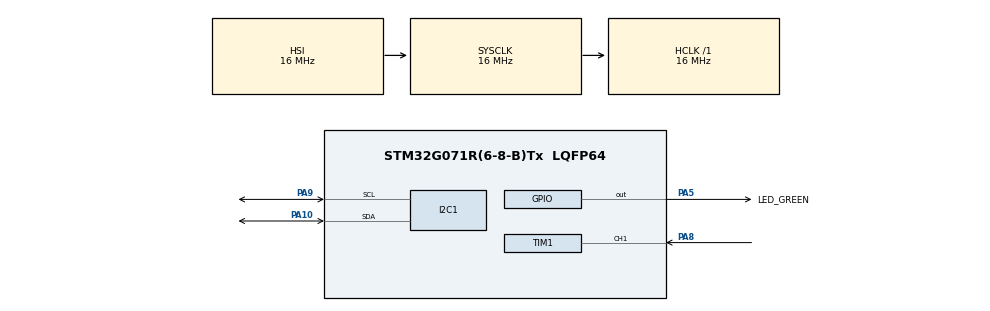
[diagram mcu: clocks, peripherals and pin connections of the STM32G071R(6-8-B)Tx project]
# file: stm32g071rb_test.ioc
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Mcu.Family=STM32G0
Mcu.Name=STM32G071R(6-8-B)Tx
Mcu.Package=LQFP64
NVIC.I2C1_IRQn=true\:0\:0\:false\:false\:true\:true\:true
NVIC.TIM1_BRK_UP_TRG_COM_IRQn=true\:0\:0\:false\:false\:true\:true\:true
NVIC.TIM1_CC_IRQn=true\:0\:0\:false\:false\:true\:true\:true
PA10.Mode=I2C
PA10.Signal=I2C1_SDA
PA13.GPIO_Label=TMS
PA13.Signal=SYS_SWDIO
PA14-BOOT0.GPIO_Label=TCK
PA14-BOOT0.Signal=SYS_SWCLK
PA2.GPIO_Label=USART2_TX [STLK_TX]
PA2.Signal=USART2_TX
PA3.GPIO_Label=USART2_RX [STLK_RX]
PA3.Signal=USART2_RX
PA5.GPIO_Label=LED_GREEN
PA5.GPIO_Speed=GPIO_SPEED_FREQ_HIGH
PA5.Signal=GPIO_Output
PA8.Signal=S_TIM1_CH1
PA9.Mode=I2C
PA9.Signal=I2C1_SCL
PC13.Signal=SYS_WKUP2
PC14-OSC32_IN\ (PC14).Signal=RCC_OSC32_IN
PC15-OSC32_OUT\ (PC15).Signal=RCC_OSC32_OUT
PF0-OSC_IN\ (PF0).GPIO_Label=MCO
PF0-OSC_IN\ (PF0).Signal=RCC_OSC_IN
ProjectManager.HeapSize=0x200
ProjectManager.StackSize=0x400
ProjectManager.TargetToolchain=STM32CubeIDE
RCC.AHBFreq_Value=16000000
RCC.CortexFreq_Value=16000000
RCC.EXTERNAL_CLOCK_VALUE=12288000
RCC.HCLKFreq_Value=16000000
RCC.HSE_VALUE=8000000
RCC.HSI_VALUE=16000000
RCC.LSE_VALUE=32768
RCC.SYSCLKFreq_VALUE=16000000
RCC.VCOOutputFreq_Value=128000000
SH.S_TIM1_CH1.0=TIM1_CH1,Input_Capture1_from_TI1
TIM1.Channel-Input_Capture1_from_TI1=TIM_CHANNEL_1
VP_SYS_VS_DBSignals.Mode=DisableDeadBatterySignals
VP_TIM1_VS_ClockSourceINT.Mode=Internal
VP_TIM1_VS_ClockSourceITR.Mode=TriggerSource_ITR0
VP_TIM1_VS_ControllerModeTrigger.Mode=Trigger Mode
board=NUCLEO-G071RB

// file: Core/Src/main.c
/* USER CODE BEGIN Header */
/**
  ******************************************************************************
  * @file           : main.c
  * @brief          : Main program body
  ******************************************************************************
  * @attention
  *
  * <h2><center>&copy; Copyright (c) 2021 STMicroelectronics.
  * All rights reserved.</center></h2>
  *
  * This software component is licensed by ST under BSD 3-Clause license,
  * the "License"; You may not use this file except in compliance with the
  * License. You may obtain a copy of the License at:
  *                        opensource.org/licenses/BSD-3-Clause
  *
  ******************************************************************************
  */
/* USER CODE END Header */
#include "main.h"
#include<stdlib.h>
#include<stdio.h>

I2C_HandleTypeDef hi2c1;

TIM_HandleTypeDef htim1;

void SystemClock_Config(void);
static void MX_GPIO_Init(void);
static void MX_I2C1_Init(void);
static void MX_TIM1_Init(void);

I2C_HandleTypeDef handle_i2c;

int main(void)
{

  /* MCU Configuration--------------------------------------------------------*/

  /* Reset of all peripherals, Initializes the Flash interface and the Systick. */
  HAL_Init();

  /* Configure the system clock */
  SystemClock_Config();

  /* Initialize all configured peripherals */
  MX_GPIO_Init();
  MX_I2C1_Init();
  MX_TIM1_Init();

  /* Infinite loop */
  /* USER CODE BEGIN WHILE */
  int slave_id = 0x01, i;
  uint8_t reg_buf[12];
  uint64_t final_data_sample;
  HAL_PWR_EnterSLEEPMode(PWR_LOWPOWERREGULATOR_ON, PWR_SLEEPENTRY_WFI);
  while (1)
  {
    /* USER CODE END WHILE */
	  if(i2c_read)
	  {
		  reg_buf[0] = 0x07;
		  final_data_sample=0;
		  HAL_I2C_Master_Transmit(&handle_i2c, slave_id, reg_buf, 1, HAL_MAX_DELAY);

		  for(i=0; i<100; i++)
		  {
			  HAL_I2C_Master_Receive(&handle_i2c, slave_id, reg_buf, 1, HAL_MAX_DELAY);
			  final_data_sample += (uint64_t)reg_buf[0];
		  }
		  printf("The final sampled I2C data is %llu\r\n",final_data_sample/100);
		  i2c_read = 0;
	  }
	  HAL_PWR_EnterSLEEPMode(PWR_LOWPOWERREGULATOR_ON, PWR_SLEEPENTRY_WFI);

  }
}

void SystemClock_Config(void)
{
  RCC_OscInitTypeDef RCC_OscInitStruct = {0};
  RCC_ClkInitTypeDef RCC_ClkInitStruct = {0};
  RCC_PeriphCLKInitTypeDef PeriphClkInit = {0};

  /** Configure the main internal regulator output voltage
  */
  HAL_PWREx_ControlVoltageScaling(PWR_REGULATOR_VOLTAGE_SCALE1);
  /** Initializes the RCC Oscillators according to the specified parameters
  * in the RCC_OscInitTypeDef structure.
  */
  RCC_OscInitStruct.OscillatorType = RCC_OSCILLATORTYPE_HSI;
  RCC_OscInitStruct.HSIState = RCC_HSI_ON;
  RCC_OscInitStruct.HSIDiv = RCC_HSI_DIV1;
  RCC_OscInitStruct.HSICalibrationValue = RCC_HSICALIBRATION_DEFAULT;
  RCC_OscInitStruct.PLL.PLLState = RCC_PLL_NONE;
  if (HAL_RCC_OscConfig(&RCC_OscInitStruct) != HAL_OK)
  {
    Error_Handler();
  }
  /** Initializes the CPU, AHB and APB buses clocks
  */
  RCC_ClkInitStruct.ClockType = RCC_CLOCKTYPE_HCLK|RCC_CLOCKTYPE_SYSCLK
                              |RCC_CLOCKTYPE_PCLK1;
  RCC_ClkInitStruct.SYSCLKSource = RCC_SYSCLKSOURCE_HSI;
  RCC_ClkInitStruct.AHBCLKDivider = RCC_SYSCLK_DIV1;
  RCC_ClkInitStruct.APB1CLKDivider = RCC_HCLK_DIV1;

  if (HAL_RCC_ClockConfig(&RCC_ClkInitStruct, FLASH_LATENCY_0) != HAL_OK)
  {
    Error_Handler();
  }
  /** Initializes the peripherals clocks
  */
  PeriphClkInit.PeriphClockSelection = RCC_PERIPHCLK_I2C1|RCC_PERIPHCLK_TIM1;
  PeriphClkInit.I2c1ClockSelection = RCC_I2C1CLKSOURCE_PCLK1;
  PeriphClkInit.Tim1ClockSelection = RCC_TIM1CLKSOURCE_PCLK1;
  if (HAL_RCCEx_PeriphCLKConfig(&PeriphClkInit) != HAL_OK)
  {
    Error_Handler();
  }
}

static void MX_I2C1_Init(void)
{

  hi2c1.Instance = I2C1;
  hi2c1.Init.Timing = 0x00303D5B;
  hi2c1.Init.OwnAddress1 = 0;
  hi2c1.Init.AddressingMode = I2C_ADDRESSINGMODE_7BIT;
  hi2c1.Init.DualAddressMode = I2C_DUALADDRESS_DISABLE;
  hi2c1.Init.OwnAddress2 = 0;
  hi2c1.Init.OwnAddress2Masks = I2C_OA2_NOMASK;
  hi2c1.Init.GeneralCallMode = I2C_GENERALCALL_DISABLE;
  hi2c1.Init.NoStretchMode = I2C_NOSTRETCH_DISABLE;
  if (HAL_I2C_Init(&hi2c1) != HAL_OK)
  {
    Error_Handler();
  }
  /** Configure Analogue filter
  */
  if (HAL_I2CEx_ConfigAnalogFilter(&hi2c1, I2C_ANALOGFILTER_ENABLE) != HAL_OK)
  {
    Error_Handler();
  }
  /** Configure Digital filter
  */
  if (HAL_I2CEx_ConfigDigitalFilter(&hi2c1, 0) != HAL_OK)
  {
    Error_Handler();
  }

}

static void MX_TIM1_Init(void)
{

  TIM_ClockConfigTypeDef sClockSourceConfig = {0};
  TIM_SlaveConfigTypeDef sSlaveConfig = {0};
  TIM_MasterConfigTypeDef sMasterConfig = {0};
  TIM_IC_InitTypeDef sConfigIC = {0};
  TIM_BreakDeadTimeConfigTypeDef sBreakDeadTimeConfig = {0};

  htim1.Instance = TIM1;
  htim1.Init.Prescaler = 255;
  htim1.Init.CounterMode = TIM_COUNTERMODE_UP;
  htim1.Init.Period = 63;//10ms interrupt
  htim1.Init.ClockDivision = TIM_CLOCKDIVISION_DIV1;
  htim1.Init.RepetitionCounter = 0;
  htim1.Init.AutoReloadPreload = TIM_AUTORELOAD_PRELOAD_DISABLE;
  if (HAL_TIM_Base_Init(&htim1) != HAL_OK)
  {
    Error_Handler();
  }
  sClockSourceConfig.ClockSource = TIM_CLOCKSOURCE_INTERNAL;
  if (HAL_TIM_ConfigClockSource(&htim1, &sClockSourceConfig) != HAL_OK)
  {
    Error_Handler();
  }
  if (HAL_TIM_IC_Init(&htim1) != HAL_OK)
  {
    Error_Handler();
  }
  sSlaveConfig.SlaveMode = TIM_SLAVEMODE_TRIGGER;
  sSlaveConfig.InputTrigger = TIM_TS_ITR0;
  if (HAL_TIM_SlaveConfigSynchro(&htim1, &sSlaveConfig) != HAL_OK)
  {
    Error_Handler();
  }
  sMasterConfig.MasterOutputTrigger = TIM_TRGO_RESET;
  sMasterConfig.MasterOutputTrigger2 = TIM_TRGO2_RESET;
  sMasterConfig.MasterSlaveMode = TIM_MASTERSLAVEMODE_DISABLE;
  if (HAL_TIMEx_MasterConfigSynchronization(&htim1, &sMasterConfig) != HAL_OK)
  {
    Error_Handler();
  }
  sConfigIC.ICPolarity = TIM_INPUTCHANNELPOLARITY_RISING;
  sConfigIC.ICSelection = TIM_ICSELECTION_DIRECTTI;
  sConfigIC.ICPrescaler = TIM_ICPSC_DIV1;
  sConfigIC.ICFilter = 0;
  if (HAL_TIM_IC_ConfigChannel(&htim1, &sConfigIC, TIM_CHANNEL_1) != HAL_OK)
  {
    Error_Handler();
  }
  sBreakDeadTimeConfig.BreakAFMode = TIM_BREAK_AFMODE_INPUT;
  sBreakDeadTimeConfig.Break2AFMode = TIM_BREAK_AFMODE_INPUT;
  if (HAL_TIMEx_ConfigBreakDeadTime(&htim1, &sBreakDeadTimeConfig) != HAL_OK)
  {
    Error_Handler();
  }

}

static void MX_GPIO_Init(void)
{
  GPIO_InitTypeDef GPIO_InitStruct = {0};

  /* GPIO Ports Clock Enable */
  __HAL_RCC_GPIOC_CLK_ENABLE();
  __HAL_RCC_GPIOF_CLK_ENABLE();
  __HAL_RCC_GPIOA_CLK_ENABLE();

  /*Configure GPIO pin Output Level */
  HAL_GPIO_WritePin(LED_GREEN_GPIO_Port, LED_GREEN_Pin, GPIO_PIN_RESET);

  /*Configure GPIO pins : USART2_TX_Pin USART2_RX_Pin */
  GPIO_InitStruct.Pin = USART2_TX_Pin|USART2_RX_Pin;
  GPIO_InitStruct.Mode = GPIO_MODE_AF_PP;
  GPIO_InitStruct.Pull = GPIO_NOPULL;
  GPIO_InitStruct.Speed = GPIO_SPEED_FREQ_LOW;
  GPIO_InitStruct.Alternate = GPIO_AF1_USART2;
  HAL_GPIO_Init(GPIOA, &GPIO_InitStruct);

  /*Configure GPIO pin : LED_GREEN_Pin */
  GPIO_InitStruct.Pin = LED_GREEN_Pin;
  GPIO_InitStruct.Mode = GPIO_MODE_OUTPUT_PP;
  GPIO_InitStruct.Pull = GPIO_NOPULL;
  GPIO_InitStruct.Speed = GPIO_SPEED_FREQ_HIGH;
  HAL_GPIO_Init(LED_GREEN_GPIO_Port, &GPIO_InitStruct);

}

void Error_Handler(void)
{
}

/************************ (C) COPYRIGHT STMicroelectronics *****END OF FILE****/
